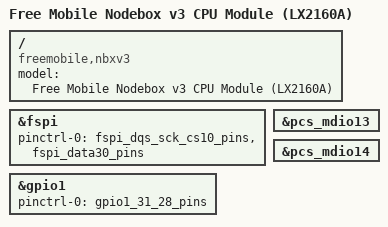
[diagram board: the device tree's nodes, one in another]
// SPDX-License-Identifier: (GPL-2.0+ OR MIT)
/*
 * Free Mobile Nodebox v3 CPU Module (LX2160A)
 *
 * Copyright 2026 Free Mobile, Vincent Jardin
 */

/dts-v1/;

#include "fsl-lx2160a-rev2.dtsi"
#include "fsl-lx2160a-nbxv3.dtsi"

/ {
	model = "Free Mobile Nodebox v3 CPU Module (LX2160A)";
	compatible = "freemobile,nbxv3", "fsl,lx2160a";
};

&fspi {
	pinctrl-names = "default";
	pinctrl-0 = <&fspi_dqs_sck_cs10_pins>, <&fspi_data30_pins>;
};

&gpio1 {
	pinctrl-names = "default";
	pinctrl-0 = <&gpio1_31_28_pins>;
};

&pcs_mdio13 {
	status = "okay";
};

&pcs_mdio14 {
	status = "okay";
};
